# CW32L012 register map
Vendor: Wuhan Xinyuan Semiconductor Co.Ltd; Series: ARMCM0P; File version: 1.2
CW32L012 Microcontroller
CPU: CM0+ r0p1, little endian, no MPU, no FPU, VTOR, 2 interrupt priority bits
Registers are 32-bit, read-write, no defined reset value unless marked. A register's access mark holds for its fields unless they carry their own. Offsets are from the block's base; lines under a group give offsets from that group; [hi:lo] are bit positions; {n}, {i} and the like mark numbered series; 'fields as' and 'values as' point back to an identical list; <NAME> marks a mode.

## Memory map
0x40000000 ADC1 size 0x7C — ADC1 peripheral
0x40000080 VC12REF size 0x4
0x40000084 VC1 size 0x10
0x40000094 VC2 size 0x10
0x400000A4 LVD size 0xC
0x400000B0 OPA1 size 0x8
0x400000B8 OPA2 size 0x8
0x400000C0 DAC size 0x38
0x400000FC BGR size 0x4
0x40000100 ADC2 size 0x7C
0x40000180 VC34REF size 0x4
0x40000184 VC3 size 0x10
0x40000194 VC4 size 0x10
0x40000400 SPI2 size 0x20
0x40000800 SPI1 size 0x20
0x40000C00 UART1 size 0x40
0x40001000 UART2 size 0x40
0x40001400 ATIM size 0x74
0x40001800 GTIM1 size 0x74 — General Timer 1
0x40001C00 GTIM2 size 0x74 — General Timer 2
0x40002000 UART3 size 0x40
0x40002400 GTIM3 size 0x74 — General Timer 3
0x40002800 GTIM4 size 0x74 — General Timer 4
0x40003400 SPI3 size 0x20
0x40004000 SYSCTRL size 0x74 — System Ctrl
0x40004080 IRMOD size 0xC
0x40004400 RTC size 0x5C
0x40004800 BTIM1 size 0x30 — Base Timer 1
0x40004840 BTIM2 size 0x30 — Base Timer 2
0x40004880 BTIM3 size 0x30 — Base Timer 3
0x40005000 IWDT size 0x28
0x40005400 WWDT size 0xC
0x40005800 I2C1 size 0x174
0x40005C00 I2C2 size 0x174
0x40006000 LPTIM size 0x24
0x40006400 HALLTIM size 0x24 — HALL Timer
0x40020000 DMA size 0xA0
0x40020020 DMACHANNEL1 size 0x20
0x40020040 DMACHANNEL2 size 0x20
0x40020060 DMACHANNEL3 size 0x20
0x40020080 DMACHANNEL4 size 0x20
0x40022000 FLASH size 0x74
0x40022400 RAM size 0x10
0x40023000 CRC size 0x10
0x40023200 EAU size 0x14
0x40023400 CORDIC size 0x10
0x48000000 GPIOA size 0x64
0x48000100 GPIOB size 0x64
0x48000200 GPIOC size 0x64
0x48000300 GPIOF size 0x64

## Interrupts
0 WDT (IWDT, WWDT) — Watch Dog Timer Interrupt
1 LVD — Low Voltage Detect Interrupt
2 RTC — Real Time Clock Interrupt
3 FLASHRAM (FLASH, RAM) — Flash/RAM Interrupt
4 SYSCTRL — SYSCTRL Interupt
5 GPIOA — GPIOA Interrupt
6 GPIOB — GPIOB Interrupt
7 GPIOC — GPIOC Interrupt
8 GPIOF — GPIOF Interrupt
9 DMACH12 (DMA, DMACHANNEL1, DMACHANNEL2) — DMA Channel 1/2 Interrupt
10 DMACH34 (DMACHANNEL3, DMACHANNEL4) — DMA Channel 3/4 Interrupt
11 CORDIC
12 ADC1 — ADC Interrupt
13 ATIM — Advanced Timer Interrupt
14 VC13 (VC1, VC3) — Voltage Comparator 1/3 Interrupt
15 VC24 (VC2, VC4) — Voltage Comparator 2/4 Interrupt
16 GTIM1 — General Timer1 Interrupt
17 GTIM2 — General Timer1 Interrupt
18 GTIM34 (GTIM3, GTIM4) — General Timer3_4 Interrupt
19 LPTIM — LPTIM Interrupt
20 BTIM1 — Base Timer1 Interrupt
21 BTIM2 — Base Timer2 Interrupt
22 BTIM3_HALLTIM (BTIM3, HALLTIM) — Base Timer3 and Hall timer Interrupt
23 I2C1 — I2C1 Interrupt
24 I2C2 — I2C2 Interrupt
25 SPI1 — SPI1 Interrupt
26 SPI23 (SPI2, SPI3) — SPI23 Interrupt
27 UART1 — UART1 Interrupt
28 UART2 — UART2 Interrupt
29 UART3 — UART3 Interrupt
30 ADC2_DAC (ADC2, DAC) — ADC2 and DAC Interrupt

## ADC1 — ADC1 peripheral
Base 0x40000000
Same registers: ADC2 0x40000100
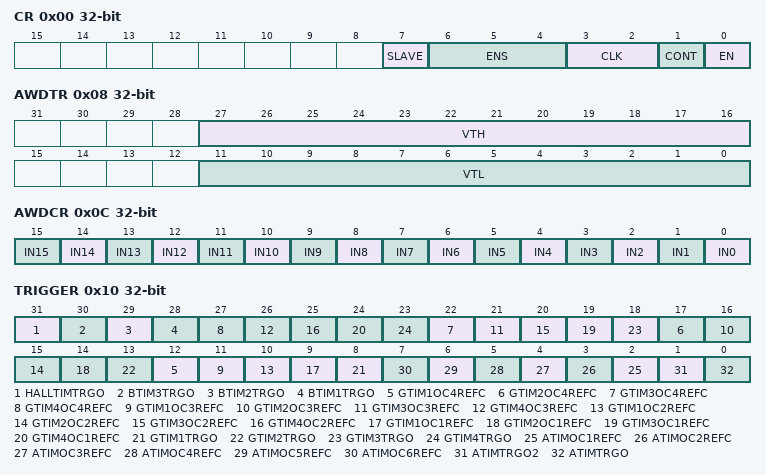
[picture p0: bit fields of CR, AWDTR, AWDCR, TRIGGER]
0x00 CR
  [7] SLAVE, [6:4] ENS, [3:2] CLK, [1] CONT, [0] EN
0x04 START
  [0] START
0x08 AWDTR
  [27:16] VTH, [11:0] VTL
0x0C AWDCR
  [n] IN{n} (n=0..15)
0x10 TRIGGER
  [31] HALLTIMTRGO, [30] BTIM3TRGO, [29] BTIM2TRGO, [28] BTIM1TRGO, [5n+7] GTIM{n}OC4REFC (n=1..4), [5n+6] GTIM{n}OC3REFC (n=1..4), [5n+5] GTIM{n}OC2REFC (n=1..4), [5n+4] GTIM{n}OC1REFC (n=1..4), [5n+3] GTIM{n}TRGO (n=1..4), [n+1] ATIMOC{n}REFC (n=1..6), [1] ATIMTRGO2, [0] ATIMTRGO
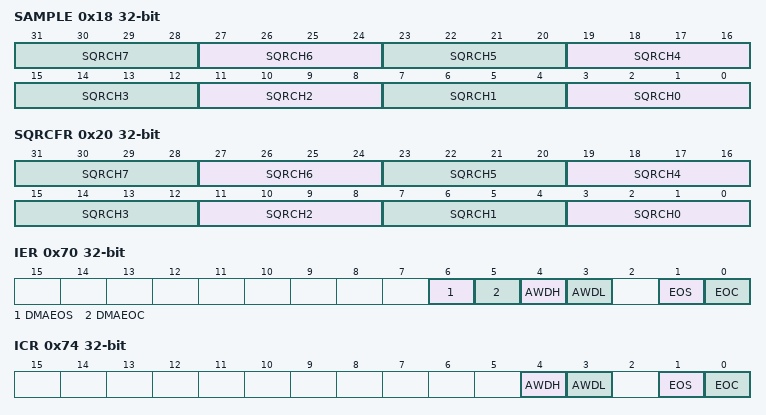
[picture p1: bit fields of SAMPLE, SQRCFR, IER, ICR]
0x18 SAMPLE
  [4n+3:4n] SQRCH{n} (n=0..7)
0x20 SQRCFR
  [4n+3:4n] SQRCH{n} (n=0..7)
{0x30+4i} RESULT{i} ro (i=0..7)
  [11:0] RESULT
0x70 IER
  [6] DMAEOS, [5] DMAEOC, [4] AWDH, [3] AWDL, [1] EOS, [0] EOC
0x74 ICR
  [4] AWDH, [3] AWDL, [1] EOS, [0] EOC
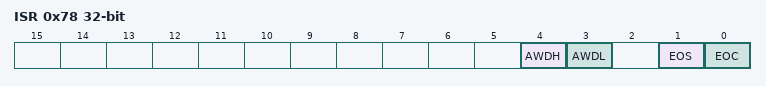
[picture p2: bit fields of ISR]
0x78 ISR
  [4] AWDH ro, [3] AWDL ro, [1] EOS ro, [0] EOC ro
